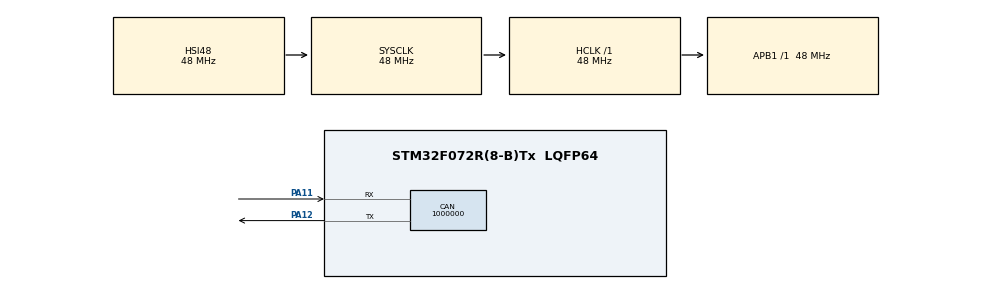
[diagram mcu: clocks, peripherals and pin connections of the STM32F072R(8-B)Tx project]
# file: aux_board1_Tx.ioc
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CAN.CalculateBaudRate=1000000
CAN.CalculateTimeBit=1000
CAN.CalculateTimeQuantum=333.3333333333333
Mcu.Family=STM32F0
Mcu.Name=STM32F072R(8-B)Tx
Mcu.Package=LQFP64
NVIC.TIM2_IRQn=true\:0\:0\:false\:false\:true\:true\:true
PA11.Mode=CAN_Activate
PA11.Signal=CAN_RX
PA12.Mode=CAN_Activate
PA12.Signal=CAN_TX
PA13.Mode=Serial_Wire
PA13.Signal=SYS_SWDIO
PA14.Mode=Serial_Wire
PA14.Signal=SYS_SWCLK
PF0-OSC_IN.Mode=HSE-External-Oscillator
PF0-OSC_IN.Signal=RCC_OSC_IN
PF1-OSC_OUT.Mode=HSE-External-Oscillator
PF1-OSC_OUT.Signal=RCC_OSC_OUT
ProjectManager.HeapSize=0x200
ProjectManager.StackSize=0x400
ProjectManager.TargetToolchain=STM32CubeIDE
RCC.AHBFreq_Value=48000000
RCC.APB1Freq_Value=48000000
RCC.APB1TimFreq_Value=48000000
RCC.HCLKFreq_Value=48000000
RCC.PLLSourceVirtual=RCC_PLLSOURCE_HSI48
RCC.SYSCLKFreq_VALUE=48000000
RCC.SYSCLKSource=RCC_SYSCLKSOURCE_HSI48
TIM2.Period=10000-1
TIM2.Prescaler=48-1
VP_TIM2_VS_ClockSourceINT.Mode=Internal
board=custom

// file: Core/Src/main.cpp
/* USER CODE BEGIN Header */
/**
  ******************************************************************************
  * @file           : main.cpp
  * @brief          : Main program body
  ******************************************************************************
  * @attention
  *
  * <h2><center>&copy; Copyright (c) 2020 STMicroelectronics.
  * All rights reserved.</center></h2>
  *
  * This software component is licensed by ST under BSD 3-Clause license,
  * the "License"; You may not use this file except in compliance with the
  * License. You may obtain a copy of the License at:
  *                        opensource.org/licenses/BSD-3-Clause
  *
  *
  * SOLAR GATORS CAN EXAMPLE
  * Aux TX board. Demonstrates the implementation of sending Aux data messages
  * Aux TX messages will be sent every 10 milliseconds to toggle the headlights.
  * Crucial information will be indicated by comments starting with "SG"
  ******************************************************************************
  */

/* USER CODE END Header */
#include "main.h"

/* USER CODE BEGIN Includes */
/**
*	SG
*	Includes the AUX_MESSAGE_0 and packet class. AUX_MESSAGE_0 is
*	a child of the base class, SUBSYSTEM_DATA_MODULE
*/
#include "subsystem-can-driver/subsystem-data-module.hpp"
#include "subsystem-can-driver/aux-data-module.hpp"

/* USER CODE END Includes */

CAN_HandleTypeDef hcan;
TIM_HandleTypeDef htim2;

/* USER CODE BEGIN PV */
volatile uint16_t timerFlag = 0;
/**
*	SG
*	Initialize the Aux TX CAN message to be sent
* 	This does not necessarily have to be done outside of main.
*/
static AUX_MESSAGE_0 aux_tx;

/* USER CODE END PV */

void SystemClock_Config(void);
static void MX_GPIO_Init(void);
static void MX_TIM2_Init(void);
static void MX_CAN_Init(void);
/* USER CODE BEGIN PFP */

// ----------------------------
// --- ISR PROTOTYPE(S) -------
// ----------------------------
/**
 *
 */
void HAL_GPIO_EXTI_Callback(uint16_t GPIO_PIN);
/**
 *
 */
void HAL_TIM_PeriodElapsedCallback(TIM_HandleTypeDef *htim);

// ---------------------------------
// --- FUNCTION PROTOTYPE(S) -------
// ---------------------------------

/* USER CODE END PFP */

int main(void)
{

  /* MCU Configuration--------------------------------------------------------*/

  /* Reset of all peripherals, Initializes the Flash interface and the Systick. */
  HAL_Init();

  /* Configure the system clock */
  SystemClock_Config();

  /* Initialize all configured peripherals */
  MX_GPIO_Init();
  MX_CAN_Init();
  MX_TIM2_Init();

  /* Infinite loop */
  /* USER CODE BEGIN WHILE */

  /**
   * SG
   * Initialize the Timer/Counter module. This is used to send
   * CAN messages on a regular interval
   */
  __HAL_TIM_SET_COUNTER(&htim2, 0);		// initial count = 0
  HAL_TIM_Base_Start_IT(&htim2);		// Start timer

  /**
  * SG
  * Initialize/modify values for the Aux TX CAN message.
  * .txData is an AUX_MESSAGE_0_DATA_PACKET struct encapsulated
  *	within the AUX_MESSAGE_0
  */
  aux_tx.txData.cplusOn 		= 1;
  aux_tx.txData.cminusOn 		= 0;
  aux_tx.txData.hornOn 			= 1;
  aux_tx.txData.regenOn 		= 0;
  aux_tx.txData.hazardsOn		= 1;
  aux_tx.txData.leftOn 			= 0;
  aux_tx.txData.rightOn 		= 1;
  aux_tx.txData.headlightsOn 	= 0;

  /**
  * SG
  * Don't forget to StartCAN!
  */
  SUBSYSTEM_DATA_MODULE::StartCAN();

  while (1)
  {
    /* USER CODE END WHILE */

    /* USER CODE BEGIN 3 */
	if (timerFlag)
	{
		timerFlag = 0;
		/**
		*	SG
		*	Send the data using SendData function.
		*/
		aux_tx.SendData();

		// toggle the headlights
		aux_tx.txData.headlightsOn = !aux_tx.txData.headlightsOn;
	}
  }
  /* USER CODE END 3 */
}

void SystemClock_Config(void)
{
  RCC_OscInitTypeDef RCC_OscInitStruct = {0};
  RCC_ClkInitTypeDef RCC_ClkInitStruct = {0};

  /** Initializes the RCC Oscillators according to the specified parameters
  * in the RCC_OscInitTypeDef structure.
  */
  RCC_OscInitStruct.OscillatorType = RCC_OSCILLATORTYPE_HSI48;
  RCC_OscInitStruct.HSI48State = RCC_HSI48_ON;
  RCC_OscInitStruct.PLL.PLLState = RCC_PLL_NONE;
  if (HAL_RCC_OscConfig(&RCC_OscInitStruct) != HAL_OK)
  {
    Error_Handler();
  }
  /** Initializes the CPU, AHB and APB buses clocks
  */
  RCC_ClkInitStruct.ClockType = RCC_CLOCKTYPE_HCLK|RCC_CLOCKTYPE_SYSCLK
                              |RCC_CLOCKTYPE_PCLK1;
  RCC_ClkInitStruct.SYSCLKSource = RCC_SYSCLKSOURCE_HSI48;
  RCC_ClkInitStruct.AHBCLKDivider = RCC_SYSCLK_DIV1;
  RCC_ClkInitStruct.APB1CLKDivider = RCC_HCLK_DIV1;

  if (HAL_RCC_ClockConfig(&RCC_ClkInitStruct, FLASH_LATENCY_1) != HAL_OK)
  {
    Error_Handler();
  }
}

static void MX_CAN_Init(void)
{

  hcan.Instance = CAN;
  hcan.Init.Prescaler = 16;
  hcan.Init.Mode = CAN_MODE_NORMAL;
  hcan.Init.SyncJumpWidth = CAN_SJW_1TQ;
  hcan.Init.TimeSeg1 = CAN_BS1_1TQ;
  hcan.Init.TimeSeg2 = CAN_BS2_1TQ;
  hcan.Init.TimeTriggeredMode = DISABLE;
  hcan.Init.AutoBusOff = DISABLE;
  hcan.Init.AutoWakeUp = DISABLE;
  hcan.Init.AutoRetransmission = DISABLE;
  hcan.Init.ReceiveFifoLocked = DISABLE;
  hcan.Init.TransmitFifoPriority = DISABLE;
  if (HAL_CAN_Init(&hcan) != HAL_OK)
  {
    Error_Handler();
  }

}

static void MX_TIM2_Init(void)
{

  TIM_ClockConfigTypeDef sClockSourceConfig = {0};
  TIM_MasterConfigTypeDef sMasterConfig = {0};

  htim2.Instance = TIM2;
  htim2.Init.Prescaler = 48-1;
  htim2.Init.CounterMode = TIM_COUNTERMODE_UP;
  htim2.Init.Period = 10000-1;
  htim2.Init.ClockDivision = TIM_CLOCKDIVISION_DIV1;
  htim2.Init.AutoReloadPreload = TIM_AUTORELOAD_PRELOAD_DISABLE;
  if (HAL_TIM_Base_Init(&htim2) != HAL_OK)
  {
    Error_Handler();
  }
  sClockSourceConfig.ClockSource = TIM_CLOCKSOURCE_INTERNAL;
  if (HAL_TIM_ConfigClockSource(&htim2, &sClockSourceConfig) != HAL_OK)
  {
    Error_Handler();
  }
  sMasterConfig.MasterOutputTrigger = TIM_TRGO_RESET;
  sMasterConfig.MasterSlaveMode = TIM_MASTERSLAVEMODE_DISABLE;
  if (HAL_TIMEx_MasterConfigSynchronization(&htim2, &sMasterConfig) != HAL_OK)
  {
    Error_Handler();
  }

}

static void MX_GPIO_Init(void)
{

  /* GPIO Ports Clock Enable */
  __HAL_RCC_GPIOF_CLK_ENABLE();
  __HAL_RCC_GPIOA_CLK_ENABLE();

}

/* USER CODE BEGIN 4 */

// -----------------------------
// --- ISR DEFINITION(S) -------
// -----------------------------
void HAL_GPIO_EXTI_Callback(uint16_t GPIO_PIN)
{
	__NOP();	// no operation

}
void HAL_TIM_PeriodElapsedCallback(TIM_HandleTypeDef *htim)
{
	// check which timer triggered interrupt
	if(htim->Instance == TIM2)
	{
		timerFlag = 1;
	}
	else __NOP();	// no operation
}

/* USER CODE END 4 */

void Error_Handler(void)
{
  __disable_irq();
  while (1)
  {
  }
}

/************************ (C) COPYRIGHT STMicroelectronics *****END OF FILE****/
